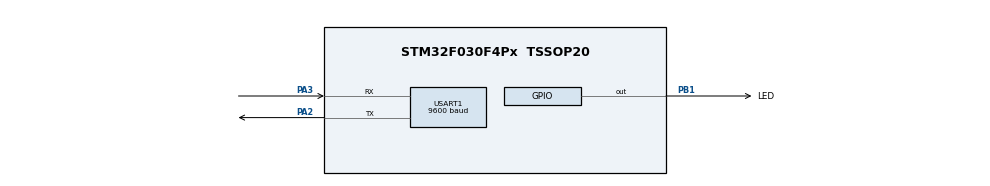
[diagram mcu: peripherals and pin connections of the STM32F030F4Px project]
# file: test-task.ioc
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FREERTOS.Tasks01=defaultTask,24,96,StartDefaultTask,Default,NULL,Dynamic,NULL,NULL
Mcu.Family=STM32F0
Mcu.Name=STM32F030F4Px
Mcu.Package=TSSOP20
NVIC.USART1_IRQn=true\:3\:0\:false\:false\:true\:true\:true\:true\:true
PA2.Mode=Asynchronous
PA2.Signal=USART1_TX
PA3.Mode=Asynchronous
PA3.Signal=USART1_RX
PB1.GPIO_Label=LED
PB1.Signal=GPIO_Output
ProjectManager.HeapSize=0x200
ProjectManager.StackSize=0x400
ProjectManager.TargetToolchain=STM32CubeIDE
USART1.BaudRate=9600
USART1.VirtualMode-Asynchronous=VM_ASYNC
VP_FREERTOS_VS_CMSIS_V2.Mode=CMSIS_V2
board=custom

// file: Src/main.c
/* USER CODE BEGIN Header */
/**
  ******************************************************************************
  * @file           : main.c
  * @brief          : Main program body
  ******************************************************************************
  * @attention
  *
  * Copyright (c) 2025 STMicroelectronics.
  * All rights reserved.
  *
  * This software is licensed under terms that can be found in the LICENSE file
  * in the root directory of this software component.
  * If no LICENSE file comes with this software, it is provided AS-IS.
  *
  ******************************************************************************
  */
/* USER CODE END Header */
#include <stdbool.h>
#include "main.h"
#include "cmsis_os.h"
#include "queue.h"
#include "task.h"

/* USER CODE BEGIN PTD */
typedef enum
{
    LED_TASK_CMD_BLINK_FASTER,
    LED_TASK_CMD_BLINK_SLOWER,
} led_task_cmd_t;
/* USER CODE END PTD */

static QueueHandle_t     led_task_cmd_queue;
volatile char sim;
UART_HandleTypeDef huart1;
static QueueHandle_t uart_rxq, uart_txq;

/* Definitions for defaultTask */
osThreadId_t defaultTaskHandle;
const osThreadAttr_t defaultTask_attributes = {
  .name = "defaultTask",
  .stack_size = 96 * 4,
  .priority = (osPriority_t) osPriorityNormal,
};
/* USER CODE BEGIN PV */
static inline void uart_putc(char ch) {
    // Queue the byte to send
    while ( xQueueSend(uart_txq,&ch,0) != pdPASS )
        taskYIELD();
}

static void task_led(void *pvParameters)
{
    uint8_t    cmd;
    TickType_t delay = pdMS_TO_TICKS(250);

    while(true)
    {
        // Toggle LED
        HAL_GPIO_TogglePin(GPIOB,GPIO_PIN_1);
        vTaskDelay(delay);

        if(xQueueReceive(led_task_cmd_queue, &cmd, 0) == pdTRUE)
        {
            // Handle command
            switch(cmd)
            {
                case LED_TASK_CMD_BLINK_FASTER:
                    // Decrease delay
                    if(delay > pdMS_TO_TICKS(50))
                    {
                        delay -= pdMS_TO_TICKS(50);
                    }
                    break;

                case LED_TASK_CMD_BLINK_SLOWER:
                    // Increase delay
                    if(delay < pdMS_TO_TICKS(500))
                    {
                        delay += pdMS_TO_TICKS(50);
                    }
                    break;

                default:{
                    uart_putc('e');
                }

                    break;
            }
        }
    }
}
/* USER CODE END PV */

void SystemClock_Config(void);
static void MX_GPIO_Init(void);
static void MX_USART1_UART_Init(void);
void StartDefaultTask(void *argument);

/* USER CODE BEGIN 0 */
static void led_task_cmd(led_task_cmd_t cmd)
{
    uint8_t item = (uint8_t)cmd;
    // Post command to LED task queue
    if(xQueueSendToBack(led_task_cmd_queue, &item, 0) != pdPASS){}
}

static void tx_task(void *args __attribute((unused))) {
    char ch;
    uint8_t str[1];

    for (;;) {
        while ( xQueueReceive(uart_txq,&ch,portMAX_DELAY) != pdPASS )
            taskYIELD();
        str[0]=(uint8_t)ch;
        // Received a char to transmit:
        while( HAL_UART_GetState (&huart1) == HAL_UART_STATE_BUSY_TX )
            taskYIELD();
        HAL_UART_Transmit_IT(&huart1, str, 1);
    }
}

static void main_task(void *args __attribute((unused))) {
    uint8_t str[2];
    for (;;) {
        while ( xQueueReceive(uart_rxq,&str,0) != pdPASS )
            taskYIELD();
        if (str[0] != 0x10) uart_putc('e');
        else led_task_cmd(str[1]);
    }
}
/* USER CODE END 0 */

int main(void)
{

  /* MCU Configuration--------------------------------------------------------*/

  /* Reset of all peripherals, Initializes the Flash interface and the Systick. */
  HAL_Init();

  /* Configure the system clock */
  SystemClock_Config();

  /* Initialize all configured peripherals */
  MX_GPIO_Init();
  MX_USART1_UART_Init();

  /* Init scheduler */
  osKernelInitialize();

  /* Create the thread(s) */
  /* creation of defaultTask */
  defaultTaskHandle = osThreadNew(StartDefaultTask, NULL, &defaultTask_attributes);

  /* Start scheduler */
  osKernelStart();

  /* We should never get here as control is now taken by the scheduler */

    led_task_cmd_queue = xQueueCreate(2, sizeof(uint8_t));
    xTaskCreate(&task_led, "LED", configMINIMAL_STACK_SIZE, NULL, 1, NULL);
    xTaskCreate(main_task,"MAIN",100,NULL,configMAX_PRIORITIES-1,NULL);
    xTaskCreate(tx_task,"UARTTX",100,NULL,configMAX_PRIORITIES-1,NULL);

    vTaskStartScheduler();

    HAL_UART_Receive_IT(&huart1, (uint8_t*)&sim, 2);
  /* Infinite loop */
  while (1)
  {

  }
}

void HAL_UART_RxCpltCallback(UART_HandleTypeDef *huart)
{
    BaseType_t hptask=pdFALSE;

    xQueueSendFromISR(uart_rxq,(uint8_t*)&sim,&hptask);
    HAL_UART_Receive_IT(&huart1, (uint8_t*)&sim, 2);
}

void SystemClock_Config(void)
{
  RCC_OscInitTypeDef RCC_OscInitStruct = {0};
  RCC_ClkInitTypeDef RCC_ClkInitStruct = {0};
  RCC_PeriphCLKInitTypeDef PeriphClkInit = {0};

  /** Initializes the RCC Oscillators according to the specified parameters
  * in the RCC_OscInitTypeDef structure.
  */
  RCC_OscInitStruct.OscillatorType = RCC_OSCILLATORTYPE_HSI;
  RCC_OscInitStruct.HSIState = RCC_HSI_ON;
  RCC_OscInitStruct.HSICalibrationValue = RCC_HSICALIBRATION_DEFAULT;
  RCC_OscInitStruct.PLL.PLLState = RCC_PLL_NONE;
  if (HAL_RCC_OscConfig(&RCC_OscInitStruct) != HAL_OK)
  {
    Error_Handler();
  }

  /** Initializes the CPU, AHB and APB buses clocks
  */
  RCC_ClkInitStruct.ClockType = RCC_CLOCKTYPE_HCLK|RCC_CLOCKTYPE_SYSCLK
                              |RCC_CLOCKTYPE_PCLK1;
  RCC_ClkInitStruct.SYSCLKSource = RCC_SYSCLKSOURCE_HSI;
  RCC_ClkInitStruct.AHBCLKDivider = RCC_SYSCLK_DIV1;
  RCC_ClkInitStruct.APB1CLKDivider = RCC_HCLK_DIV1;

  if (HAL_RCC_ClockConfig(&RCC_ClkInitStruct, FLASH_LATENCY_0) != HAL_OK)
  {
    Error_Handler();
  }
  PeriphClkInit.PeriphClockSelection = RCC_PERIPHCLK_USART1;
  PeriphClkInit.Usart1ClockSelection = RCC_USART1CLKSOURCE_PCLK1;
  if (HAL_RCCEx_PeriphCLKConfig(&PeriphClkInit) != HAL_OK)
  {
    Error_Handler();
  }
}

static void MX_USART1_UART_Init(void)
{

  huart1.Instance = USART1;
  huart1.Init.BaudRate = 9600;
  huart1.Init.WordLength = UART_WORDLENGTH_8B;
  huart1.Init.StopBits = UART_STOPBITS_1;
  huart1.Init.Parity = UART_PARITY_NONE;
  huart1.Init.Mode = UART_MODE_TX_RX;
  huart1.Init.HwFlowCtl = UART_HWCONTROL_NONE;
  huart1.Init.OverSampling = UART_OVERSAMPLING_16;
  huart1.Init.OneBitSampling = UART_ONE_BIT_SAMPLE_DISABLE;
  huart1.AdvancedInit.AdvFeatureInit = UART_ADVFEATURE_NO_INIT;
  if (HAL_UART_Init(&huart1) != HAL_OK)
  {
    Error_Handler();
  }

}

static void MX_GPIO_Init(void)
{
  GPIO_InitTypeDef GPIO_InitStruct = {0};

  /* GPIO Ports Clock Enable */
  __HAL_RCC_GPIOA_CLK_ENABLE();
  __HAL_RCC_GPIOB_CLK_ENABLE();

  /*Configure GPIO pin Output Level */
  HAL_GPIO_WritePin(LED_GPIO_Port, LED_Pin, GPIO_PIN_RESET);

  /*Configure GPIO pin : LED_Pin */
  GPIO_InitStruct.Pin = LED_Pin;
  GPIO_InitStruct.Mode = GPIO_MODE_OUTPUT_PP;
  GPIO_InitStruct.Pull = GPIO_NOPULL;
  GPIO_InitStruct.Speed = GPIO_SPEED_FREQ_LOW;
  HAL_GPIO_Init(LED_GPIO_Port, &GPIO_InitStruct);

}

void StartDefaultTask(void *argument)
{
  for(;;)
  {
    osDelay(1);
  }
}

void Error_Handler(void)
{
  __disable_irq();
  while (1)
  {
  }
}
